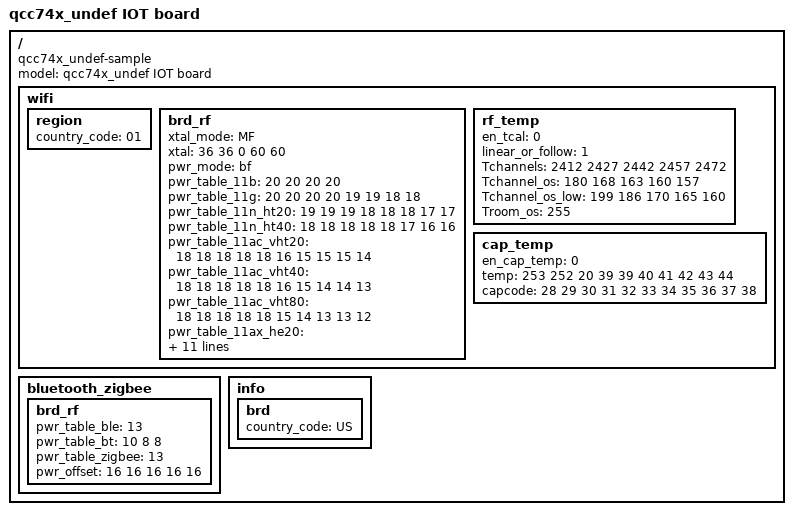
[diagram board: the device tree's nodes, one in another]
/dts-v1/;
// version: 17
// last_comp_version: 16
// boot_cpuid_phys: 0x0

/ {
    model = "qcc74x_undef IOT board";
    compatible = "qcc74x_undef-sample", "qcc74x_undef-common";
    #address-cells = <0x1>;
    #size-cells = <0x1>;
    wifi {
        #address-cells = <1>;
        #size-cells = <1>;
        region {
            country_code = <01>;
        };
        brd_rf {
            xtal_mode = "MF";
            xtal = <36 36 0 60 60>;
            pwr_mode = "bf";//B: only use power offset in EFUSE; b: use power offset in EFUSE with incremental mode; F: only use power offset in Flash; f: use power offset in Flash with incremental mode
            pwr_table_11b        = <20 20 20 20>;//1Mbps 2Mbps 5.5Mbps 11Mbps
            pwr_table_11g        = <20 20 20 20 19 19 18 18>; //6Mbps 9Mbps 12Mbps 18MBps 24Mbps 36Mbps 48Mbps 54Mbps
            pwr_table_11n_ht20  = <19 19 19 18 18 18 17 17>; //MCS0~MCS7
            pwr_table_11n_ht40  = <18 18 18 18 18 17 16 16>; //MCS0~MCS7
            pwr_table_11ac_vht20 = <18 18 18 18 18 16 15 15 15 14>; //MSC0~MSC9
            pwr_table_11ac_vht40 = <18 18 18 18 18 16 15 14 14 13>; //MSC0~MSC9
            pwr_table_11ac_vht80 = <18 18 18 18 18 15 14 13 13 12>; //MSC0~MSC9
            pwr_table_11ax_he20  = <19 19 19 18 18 16 15 16 16 16 13 13>; //MSC0~MSC11
            pwr_table_11ax_he40  = <19 19 19 18 18 16 16 15 15 15 12 12>; //MSC0~MSC11
            pwr_table_11ax_he80  = <18 18 18 18 18 15 14 13 13 12 11 11>; //MSC0~MSC11
            pwr_table_11ax_he160 = <18 18 18 18 18 15 14 13 12 11 10 10>; //MSC0~MSC11

            pwr_offset = <16 16 16 16 16 16 16 16 16 16 16 16 16 16>;//due to the limit of current DTC, negative value is used. So we work around by adding all the poweroffset with 16.
            pwr_offset_lp = <16 16 16 16 16 16 16 16 16 16 16 16 16 16>;
            //so 14 represents -0.5dBm; 16 represents 0dBm; 20 represents 1dBm;(step is 0.25dBm)
        };
        rf_temp {
            en_tcal = <0>;
            linear_or_follow = <1>;
            Tchannels       = <2412 2427 2442 2457 2472>;
            Tchannel_os     = <180  168  163  160  157>;
            Tchannel_os_low = <199  186  170  165  160>;
            Troom_os        = <255>;
            //negative value is NOT supported. So we use '256' for 0, '255' for -1, '257' for 1,'511' for 256
        };
		cap_temp {
            en_cap_temp = <0>; //0x0060 length 1
            temp = <253 252 20 39 39 40 41 42 43 44 >; //0x0061 length 10
            capcode = <28 29 30 31 32 33 34 35 36 37 38 >; //0x0062 length 11
        };
    };
    bluetooth_zigbee {
        #address-cells = <1>;
        #size-cells = <1>;
        brd_rf {
            pwr_table_ble = <13>; //range:0~15dbm
            pwr_table_bt = <10 8 8>; //BR 1M,EDR 2M,EDR 3M
            pwr_table_zigbee = <13>; //range:0~15dbm
            pwr_offset = <16 16 16 16 16>; //step is 0.25dBm
        };
    };
    info {
        #address-cells = <1>;
        #size-cells = <1>;
        brd {
            country_code = "US";
        };
    };
};
